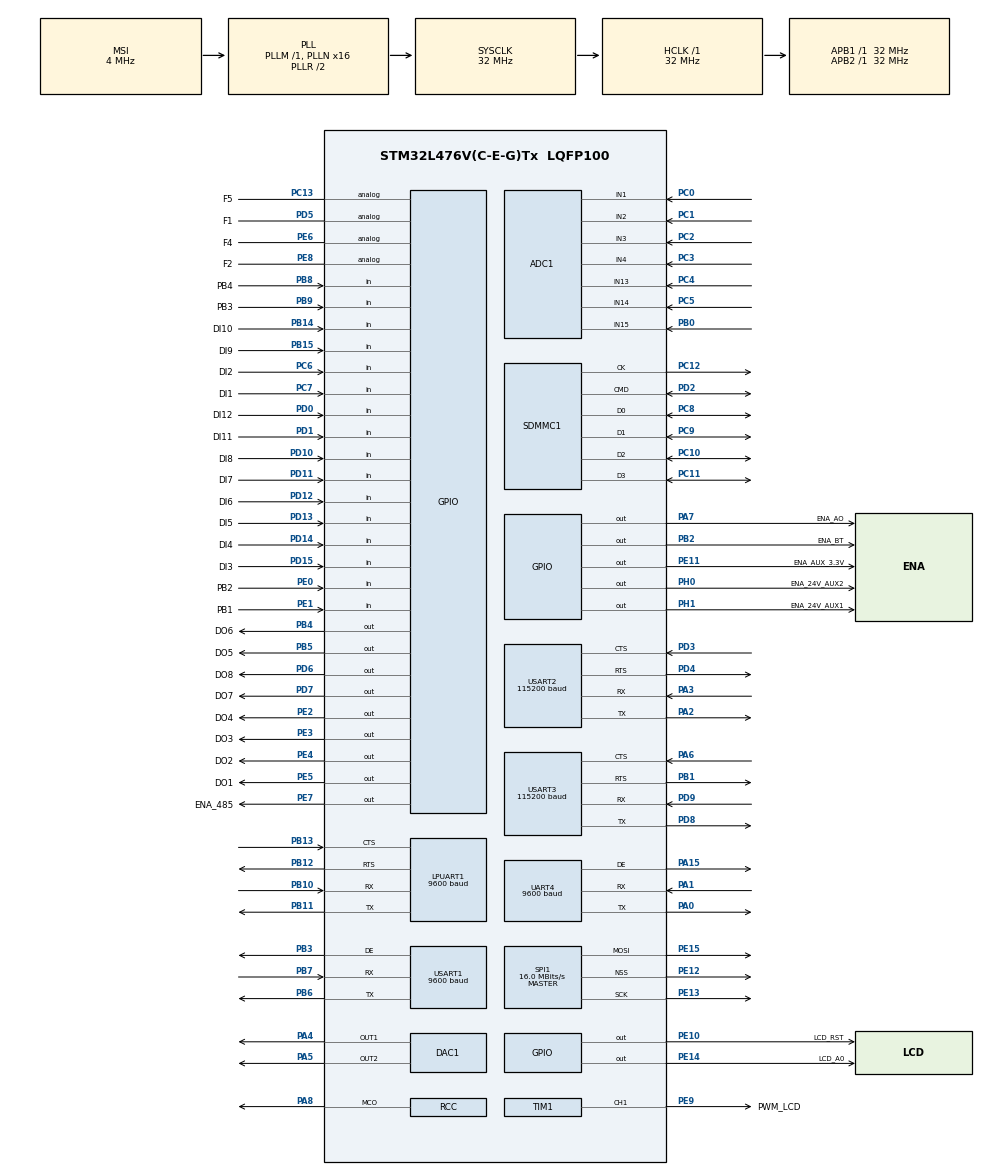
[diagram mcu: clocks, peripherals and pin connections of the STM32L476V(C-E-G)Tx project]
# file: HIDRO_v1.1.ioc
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ADC1.Channel-0\#ChannelRegularConversion=ADC_CHANNEL_4
ADC1.ClockPrescaler=ADC_CLOCK_ASYNC_DIV2
ADC1.NbrOfConversion=1
ADC1.NbrOfConversionFlag=1
ADC1.OffsetNumber-0\#ChannelRegularConversion=ADC_OFFSET_NONE
ADC1.Overrun=ADC_OVR_DATA_OVERWRITTEN
ADC1.Rank-0\#ChannelRegularConversion=1
ADC1.SamplingTime-0\#ChannelRegularConversion=ADC_SAMPLETIME_2CYCLES_5
ADC1.master=1
DAC1.DAC_Channel-DAC_OUT2=DAC_CHANNEL_2
Dma.Request0=SDMMC1_RX
Dma.Request1=SDMMC1_TX
Dma.SDMMC1_RX.0.Direction=DMA_PERIPH_TO_MEMORY
Dma.SDMMC1_RX.0.Instance=DMA2_Channel4
Dma.SDMMC1_RX.0.MemDataAlignment=DMA_MDATAALIGN_WORD
Dma.SDMMC1_RX.0.MemInc=DMA_MINC_ENABLE
Dma.SDMMC1_RX.0.Mode=DMA_NORMAL
Dma.SDMMC1_RX.0.PeriphDataAlignment=DMA_PDATAALIGN_WORD
Dma.SDMMC1_RX.0.PeriphInc=DMA_PINC_DISABLE
Dma.SDMMC1_RX.0.Priority=DMA_PRIORITY_LOW
Dma.SDMMC1_TX.1.Direction=DMA_MEMORY_TO_PERIPH
Dma.SDMMC1_TX.1.Instance=DMA2_Channel5
Dma.SDMMC1_TX.1.MemDataAlignment=DMA_MDATAALIGN_WORD
Dma.SDMMC1_TX.1.MemInc=DMA_MINC_ENABLE
Dma.SDMMC1_TX.1.Mode=DMA_NORMAL
Dma.SDMMC1_TX.1.PeriphDataAlignment=DMA_PDATAALIGN_WORD
Dma.SDMMC1_TX.1.PeriphInc=DMA_PINC_DISABLE
Dma.SDMMC1_TX.1.Priority=DMA_PRIORITY_LOW
FATFS.BSP.number=1
FATFS0.BSP.STBoard=false
FATFS0.BSP.api=Unknown
FATFS0.BSP.i2caddr=0
FATFS0.BSP.instance=PC7
FATFS0.BSP.ip=GPIO
FATFS0.BSP.mode=Input
FATFS0.BSP.name=Detect_SDIO
FATFS0.BSP.solution=PC7
IWDG.Prescaler=IWDG_PRESCALER_32
LPUART1.BaudRate=9600
LPUART1.WordLength=UART_WORDLENGTH_8B
Mcu.Family=STM32L4
Mcu.Name=STM32L476V(C-E-G)Tx
Mcu.Package=LQFP100
NVIC.DMA2_Channel4_IRQn=true\:0\:0\:false\:false\:true\:false\:true
NVIC.DMA2_Channel5_IRQn=true\:0\:0\:false\:false\:true\:false\:true
NVIC.LPUART1_IRQn=true\:0\:0\:false\:true\:true\:6\:true\:true
NVIC.PriorityGroup=NVIC_PRIORITYGROUP_4
NVIC.RTC_WKUP_IRQn=true\:0\:0\:false\:true\:true\:1\:true\:true
NVIC.SDMMC1_IRQn=true\:0\:0\:false\:false\:true\:true\:true
NVIC.UART4_IRQn=true\:0\:0\:false\:true\:true\:5\:true\:true
NVIC.USART1_IRQn=true\:0\:0\:false\:true\:true\:2\:true\:true
NVIC.USART2_IRQn=true\:0\:0\:false\:true\:true\:3\:true\:true
NVIC.USART3_IRQn=true\:0\:0\:false\:true\:true\:4\:true\:true
PA0.Mode=Asynchronous
PA0.Signal=UART4_TX
PA1.Mode=Asynchronous
PA1.Signal=UART4_RX
PA10.Signal=USB_OTG_FS_ID
PA11.Signal=USB_OTG_FS_DM
PA12.Signal=USB_OTG_FS_DP
PA13\ (JTMS-SWDIO).Mode=Serial_Wire
PA13\ (JTMS-SWDIO).Signal=SYS_JTMS-SWDIO
PA14\ (JTCK-SWCLK).Mode=Serial_Wire
PA14\ (JTCK-SWCLK).Signal=SYS_JTCK-SWCLK
PA15\ (JTDI).Mode=Hardware Flow Control (RS485)
PA15\ (JTDI).Signal=UART4_DE
PA2.Mode=Asynchronous
PA2.Signal=USART2_TX
PA3.Mode=Asynchronous
PA3.Signal=USART2_RX
PA4.Signal=COMP_DAC11_group
PA5.Signal=COMP_DAC12_group
PA6.Mode=CTS_RTS
PA6.Signal=USART3_CTS
PA7.GPIO_Label=ENA_AO
PA7.Signal=GPIO_Output
PA8.Mode=Clock-out
PA8.Signal=RCC_MCO
PA9.Signal=USB_OTG_FS_VBUS
PB0.Signal=ADCx_IN15
PB1.Mode=CTS_RTS
PB1.Signal=USART3_RTS
PB10.Mode=Asynchronous
PB10.Signal=LPUART1_RX
PB11.Mode=Asynchronous
PB11.Signal=LPUART1_TX
PB12.Mode=CTS_RTS
PB12.Signal=LPUART1_RTS
PB13.Mode=CTS_RTS
PB13.Signal=LPUART1_CTS
PB14.GPIO_Label=DI10
PB14.Signal=GPIO_Input
PB15.GPIO_Label=DI9
PB15.Signal=GPIO_Input
PB2.GPIO_Label=ENA_BT
PB2.PinState=GPIO_PIN_SET
PB2.Signal=GPIO_Output
PB3\ (JTDO-TRACESWO).Mode=Hardware Flow Control (RS485)
PB3\ (JTDO-TRACESWO).Signal=USART1_DE
PB4\ (NJTRST).GPIO_Label=DO6
PB4\ (NJTRST).Signal=GPIO_Output
PB5.GPIO_Label=DO5
PB5.Signal=GPIO_Output
PB6.Mode=Asynchronous
PB6.Signal=USART1_TX
PB7.Mode=Asynchronous
PB7.Signal=USART1_RX
PB8.GPIO_Label=PB4
PB8.Signal=GPIO_Input
PB9.GPIO_Label=PB3
PB9.Signal=GPIO_Input
PC0.Signal=ADCx_IN1
PC1.Signal=ADCx_IN2
PC10.Mode=SD_4_bits_Wide_bus
PC10.Signal=SDMMC1_D2
PC11.Mode=SD_4_bits_Wide_bus
PC11.Signal=SDMMC1_D3
PC12.Mode=SD_4_bits_Wide_bus
PC12.Signal=SDMMC1_CK
PC13.GPIO_Label=F5
PC13.Signal=GPIO_Analog
PC14-OSC32_IN\ (PC14).Mode=LSE-External-Oscillator
PC14-OSC32_IN\ (PC14).Signal=RCC_OSC32_IN
PC15-OSC32_OUT\ (PC15).Mode=LSE-External-Oscillator
PC15-OSC32_OUT\ (PC15).Signal=RCC_OSC32_OUT
PC2.Signal=ADCx_IN3
PC3.Signal=ADCx_IN4
PC4.Signal=ADCx_IN13
PC5.Signal=ADCx_IN14
PC6.GPIO_Label=DI2
PC6.Signal=GPIO_Input
PC7.GPIO_Label=DI1
PC7.Signal=GPIO_Input
PC8.Mode=SD_4_bits_Wide_bus
PC8.Signal=SDMMC1_D0
PC9.Mode=SD_4_bits_Wide_bus
PC9.Signal=SDMMC1_D1
PD0.GPIO_Label=DI12
PD0.Signal=GPIO_Input
PD1.GPIO_Label=DI11
PD1.Signal=GPIO_Input
PD10.GPIO_Label=DI8
PD10.Signal=GPIO_Input
PD11.GPIO_Label=DI7
PD11.Signal=GPIO_Input
PD12.GPIO_Label=DI6
PD12.Signal=GPIO_Input
PD13.GPIO_Label=DI5
PD13.Signal=GPIO_Input
PD14.GPIO_Label=DI4
PD14.Signal=GPIO_Input
PD15.GPIO_Label=DI3
PD15.Signal=GPIO_Input
PD2.Mode=SD_4_bits_Wide_bus
PD2.Signal=SDMMC1_CMD
PD3.Mode=CTS_RTS
PD3.Signal=USART2_CTS
PD4.Mode=CTS_RTS
PD4.Signal=USART2_RTS
PD5.GPIO_Label=F1
PD5.Signal=GPIO_Analog
PD6.GPIO_Label=DO8
PD6.Signal=GPIO_Output
PD7.GPIO_Label=DO7
PD7.Signal=GPIO_Output
PD8.Mode=Asynchronous
PD8.Signal=USART3_TX
PD9.Mode=Asynchronous
PD9.Signal=USART3_RX
PE0.GPIO_Label=PB2
PE0.Signal=GPIO_Input
PE1.GPIO_Label=PB1
PE1.Signal=GPIO_Input
PE10.GPIO_Label=LCD_RST
PE10.Signal=GPIO_Output
PE11.GPIO_Label=ENA_AUX_3.3V
PE11.Signal=GPIO_Output
PE12.Mode=NSS_Signal_Hard_Output
PE12.Signal=SPI1_NSS
PE13.Mode=TX_Only_Simplex_Unidirect_Master
PE13.Signal=SPI1_SCK
PE14.GPIO_Label=LCD_A0
PE14.Signal=GPIO_Output
PE15.Mode=TX_Only_Simplex_Unidirect_Master
PE15.Signal=SPI1_MOSI
PE2.GPIO_Label=DO4
PE2.Signal=GPIO_Output
PE3.GPIO_Label=DO3
PE3.Signal=GPIO_Output
PE4.GPIO_Label=DO2
PE4.Signal=GPIO_Output
PE5.GPIO_Label=DO1
PE5.Signal=GPIO_Output
PE6.GPIO_Label=F4
PE6.Signal=GPIO_Analog
PE7.GPIO_Label=ENA_485
PE7.PinState=GPIO_PIN_SET
PE7.Signal=GPIO_Output
PE8.GPIO_Label=F2
PE8.Signal=GPIO_Analog
PE9.GPIO_Label=PWM_LCD
PE9.Signal=S_TIM1_CH1
PH0-OSC_IN\ (PH0).GPIO_Label=ENA_24V_AUX2
PH0-OSC_IN\ (PH0).Signal=GPIO_Output
PH1-OSC_OUT\ (PH1).GPIO_Label=ENA_24V_AUX1
PH1-OSC_OUT\ (PH1).Signal=GPIO_Output
ProjectManager.HeapSize=0x400
ProjectManager.StackSize=0x800
ProjectManager.TargetToolchain=EWARM V7
RCC.ADCCLockSelection=RCC_ADCCLKSOURCE_SYSCLK
RCC.ADCFreq_Value=32000000
RCC.AHBFreq_Value=32000000
RCC.APB1Freq_Value=32000000
RCC.APB1TimFreq_Value=32000000
RCC.APB2Freq_Value=32000000
RCC.APB2TimFreq_Value=32000000
RCC.CortexFreq_Value=32000000
RCC.HCLKFreq_Value=32000000
RCC.HSE_VALUE=8000000
RCC.HSI_VALUE=16000000
RCC.LPUART1CLockSelection=RCC_LPUART1CLKSOURCE_HSI
RCC.MSI_VALUE=4000000
RCC.PLLN=16
RCC.PLLSAI1N=24
RCC.PREFETCH_ENABLE=1
RCC.RTCClockSelection=RCC_RTCCLKSOURCE_LSE
RCC.SYSCLKFreq_VALUE=32000000
RCC.SYSCLKSource=RCC_SYSCLKSOURCE_PLLCLK
RCC.UART4CLockSelection=RCC_UART4CLKSOURCE_HSI
RCC.USART1CLockSelection=RCC_USART1CLKSOURCE_HSI
RCC.USART2CLockSelection=RCC_USART2CLKSOURCE_HSI
RCC.USART3CLockSelection=RCC_USART3CLKSOURCE_HSI
RCC.USBFreq_Value=48000000
RCC.VCOOutputFreq_Value=64000000
RTC.Date=4
RTC.WakeUpClock-WakeUp=RTC_WAKEUPCLOCK_CK_SPRE_16BITS
RTC.Year=21
SDMMC1.ClockDiv=8
SH.ADCx_IN1.0=ADC1_IN1,IN1-Single-Ended
SH.ADCx_IN13.0=ADC1_IN13,IN13-Single-Ended
SH.ADCx_IN14.0=ADC1_IN14,IN14-Single-Ended
SH.ADCx_IN15.0=ADC1_IN15,IN15-Single-Ended
SH.ADCx_IN2.0=ADC1_IN2,IN2-Single-Ended
SH.ADCx_IN3.0=ADC1_IN3,IN3-Single-Ended
SH.ADCx_IN4.0=ADC1_IN4,IN4-Single-Ended
SH.COMP_DAC11_group.0=DAC1_OUT1,DAC_OUT1
SH.COMP_DAC12_group.0=DAC1_OUT2,DAC_OUT2
SH.S_TIM1_CH1.0=TIM1_CH1,PWM Generation1 CH1
SPI1.BaudRatePrescaler=SPI_BAUDRATEPRESCALER_2
SPI1.CalculateBaudRate=16.0 MBits/s
SPI1.DataSize=SPI_DATASIZE_8BIT
SPI1.Direction=SPI_DIRECTION_2LINES
SPI1.Mode=SPI_MODE_MASTER
SPI1.VirtualNSS=VM_NSSHARD
SPI1.VirtualType=VM_MASTER
TIM1.Channel-PWM\ Generation1\ CH1=TIM_CHANNEL_1
TIM1.Period=32000
TIM1.Pulse-PWM\ Generation1\ CH1=2000
TIM2.Period=0xFFFF-1
TIM2.Prescaler=32-1
UART4.BaudRate=9600
UART4.WordLength=WORDLENGTH_8B
USART1.BaudRate=9600
USART1.VirtualMode-Asynchronous=VM_ASYNC
USART1.VirtualMode-Hardware\ Flow\ Control\ (RS485)=VM_ASYNC
USART1.WordLength=WORDLENGTH_8B
USART2.BaudRate=115200
USART2.VirtualMode-Asynchronous=VM_ASYNC
USART2.WordLength=WORDLENGTH_8B
USART3.BaudRate=115200
USART3.VirtualMode-Asynchronous=VM_ASYNC
USART3.WordLength=WORDLENGTH_8B
VP_ADC1_Vref_Input.Mode=IN-Vrefint
VP_FATFS_VS_SDIO.Mode=SDIO
VP_IWDG_VS_IWDG.Mode=IWDG_Activate
VP_RTC_VS_RTC_Activate.Mode=RTC_Enabled
VP_RTC_VS_RTC_Calendar.Mode=RTC_Calendar
VP_RTC_VS_RTC_WakeUp_intern.Mode=WakeUp
VP_TIM1_VS_ClockSourceINT.Mode=Internal
VP_TIM2_VS_ClockSourceINT.Mode=Internal
board=MEP7000_v4.0

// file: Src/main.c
/* USER CODE BEGIN Header */
/**
  ******************************************************************************
  * @file           : main.c
  * @brief          : Main program body
  ******************************************************************************
  * @attention
  *
  * <h2><center>&copy; Copyright (c) 2021 STMicroelectronics.
  * All rights reserved.</center></h2>
  *
  * This software component is licensed by ST under Ultimate Liberty license
  * SLA0044, the "License"; You may not use this file except in compliance with
  * the License. You may obtain a copy of the License at:
  *                             www.st.com/SLA0044
  *
  ******************************************************************************
  */
/* USER CODE END Header */
#include "main.h"
#include "adc.h"
#include "dac.h"
#include "dma.h"
#include "fatfs.h"
#include "iwdg.h"
#include "usart.h"
#include "rtc.h"
#include "sdmmc.h"
#include "spi.h"
#include "tim.h"
#include "gpio.h"

/* USER CODE BEGIN Includes */
#include "adc_sample.h"
#include "button.h"
#include "config_flash.h"
#include "datetime.h"
#include "di.h"
#include "irrigation.h"
#include "lcd.h"
#include "sd_storage.h"
#include "ui.h"
#include "weather.h"

/* USER CODE END Includes */

/* USER CODE BEGIN PV */
/* Private variables ---------------------------------------------------------*/
volatile tREG32 Flags;
/* USER CODE END PV */

void SystemClock_Config(void);
static void MX_NVIC_Init(void);
/* USER CODE BEGIN PFP */
/* Private function prototypes -----------------------------------------------*/

/* USER CODE END PFP */

/* USER CODE BEGIN 0 */
void HAL_RTCEx_WakeUpTimerEventCallback(RTC_HandleTypeDef *hrtc)
{
  Flag_Main_1s_Event = 1;
}

/* USER CODE END 0 */

int main(void)
{

  /* MCU Configuration--------------------------------------------------------*/

  /* Reset of all peripherals, Initializes the Flash interface and the Systick. */
  HAL_Init();

  /* Configure the system clock */
  SystemClock_Config();

  /* USER CODE BEGIN SysInit */

//  HAL_SYSCFG_EnableVREFBUF(); // Enable
//  HAL_SYSCFG_VREFBUF_VoltageScalingConfig(SYSCFG_VREFBUF_VOLTAGE_SCALE1); // 2.5V
//  HAL_SYSCFG_VREFBUF_HighImpedanceConfig(SYSCFG_VREFBUF_HIGH_IMPEDANCE_DISABLE); // Vref+ connected to Vrefbuf
//  HAL_SYSCFG_DisableVREFBUF();

  /* USER CODE END SysInit */

  /* Initialize all configured peripherals */
  MX_GPIO_Init();
  MX_DMA_Init();
  MX_ADC1_Init();
  MX_DAC1_Init();
  MX_IWDG_Init();
  MX_LPUART1_UART_Init();
  MX_UART4_Init();
  MX_USART1_UART_Init();
  MX_USART2_UART_Init();
  MX_USART3_UART_Init();
  MX_RTC_Init();
  MX_SDMMC1_SD_Init();
  MX_SPI1_Init();
  MX_TIM1_Init();
  MX_TIM2_Init();
  MX_FATFS_Init();

  /* Initialize interrupts */
  MX_NVIC_Init();
  /* USER CODE BEGIN 2 */

  // Load flash into ram
  get_flash();

  // Inits
  LCDInit();
  Flag_LCD_On = 1;
  refresh_global_datetime();
  ui_init();
  clear_buttons();
  sd_init();

  HAL_TIM_Base_Start(&htim2);
	HAL_GPIO_WritePin(DO8_GPIO_Port, DO8_Pin, GPIO_PIN_SET);

  Flag_ADC_Electrode_Ready = 1;            //BORRAR, SOLO PARA PUREBA

  /* USER CODE END 2 */

  /* Infinite loop */
  while (1)
  {

    /* USER CODE BEGIN 3 */
    // One second tick
    if(Flag_Main_1s_Event)
    {
      Flag_Main_1s_Event = 0;
      iwdg_refresh();
      refresh_global_datetime();

//      adc_1s_tick();      No sirve para nada
      irrigation_1s_tick();
      weather_1s_tick();
      ui_1s_tick();
      sd_1s_tick();

    //! ! ! ! ! ! ! ! ! ! ! ! ! ! ! ! ! ! ! ! ! ! ! ! ! ! ! ! ! ! ! ! ! ! ! ! !
      Flag_ADC_Cmd_Ph=1;
      Flag_ADC_Cmd_Ec=1;
      //! ! ! ! ! ! ! ! ! ! ! ! ! ! ! ! ! ! ! ! ! ! ! ! ! ! ! ! ! ! ! ! ! ! ! ! !
    }

    adc_task();
    buttons_task();
    di_task();
    irrigation_task();
    weather_task();
    ui_task();
    sd_task();

  }
  /* USER CODE END 3 */
}

void SystemClock_Config(void)
{
  RCC_OscInitTypeDef RCC_OscInitStruct = {0};
  RCC_ClkInitTypeDef RCC_ClkInitStruct = {0};
  RCC_PeriphCLKInitTypeDef PeriphClkInit = {0};

  /** Configure LSE Drive Capability
  */
  HAL_PWR_EnableBkUpAccess();
  __HAL_RCC_LSEDRIVE_CONFIG(RCC_LSEDRIVE_LOW);
  /** Initializes the RCC Oscillators according to the specified parameters
  * in the RCC_OscInitTypeDef structure.
  */
  RCC_OscInitStruct.OscillatorType = RCC_OSCILLATORTYPE_HSI|RCC_OSCILLATORTYPE_LSI
                              |RCC_OSCILLATORTYPE_LSE|RCC_OSCILLATORTYPE_MSI;
  RCC_OscInitStruct.LSEState = RCC_LSE_ON;
  RCC_OscInitStruct.HSIState = RCC_HSI_ON;
  RCC_OscInitStruct.HSICalibrationValue = RCC_HSICALIBRATION_DEFAULT;
  RCC_OscInitStruct.LSIState = RCC_LSI_ON;
  RCC_OscInitStruct.MSIState = RCC_MSI_ON;
  RCC_OscInitStruct.MSICalibrationValue = 0;
  RCC_OscInitStruct.MSIClockRange = RCC_MSIRANGE_6;
  RCC_OscInitStruct.PLL.PLLState = RCC_PLL_ON;
  RCC_OscInitStruct.PLL.PLLSource = RCC_PLLSOURCE_MSI;
  RCC_OscInitStruct.PLL.PLLM = 1;
  RCC_OscInitStruct.PLL.PLLN = 16;
  RCC_OscInitStruct.PLL.PLLP = RCC_PLLP_DIV7;
  RCC_OscInitStruct.PLL.PLLQ = RCC_PLLQ_DIV2;
  RCC_OscInitStruct.PLL.PLLR = RCC_PLLR_DIV2;
  if (HAL_RCC_OscConfig(&RCC_OscInitStruct) != HAL_OK)
  {
    Error_Handler();
  }
  /** Initializes the CPU, AHB and APB buses clocks
  */
  RCC_ClkInitStruct.ClockType = RCC_CLOCKTYPE_HCLK|RCC_CLOCKTYPE_SYSCLK
                              |RCC_CLOCKTYPE_PCLK1|RCC_CLOCKTYPE_PCLK2;
  RCC_ClkInitStruct.SYSCLKSource = RCC_SYSCLKSOURCE_PLLCLK;
  RCC_ClkInitStruct.AHBCLKDivider = RCC_SYSCLK_DIV1;
  RCC_ClkInitStruct.APB1CLKDivider = RCC_HCLK_DIV1;
  RCC_ClkInitStruct.APB2CLKDivider = RCC_HCLK_DIV1;

  if (HAL_RCC_ClockConfig(&RCC_ClkInitStruct, FLASH_LATENCY_1) != HAL_OK)
  {
    Error_Handler();
  }
  PeriphClkInit.PeriphClockSelection = RCC_PERIPHCLK_RTC|RCC_PERIPHCLK_USART1
                              |RCC_PERIPHCLK_USART2|RCC_PERIPHCLK_USART3
                              |RCC_PERIPHCLK_UART4|RCC_PERIPHCLK_LPUART1
                              |RCC_PERIPHCLK_SDMMC1|RCC_PERIPHCLK_ADC;
  PeriphClkInit.Usart1ClockSelection = RCC_USART1CLKSOURCE_HSI;
  PeriphClkInit.Usart2ClockSelection = RCC_USART2CLKSOURCE_HSI;
  PeriphClkInit.Usart3ClockSelection = RCC_USART3CLKSOURCE_HSI;
  PeriphClkInit.Uart4ClockSelection = RCC_UART4CLKSOURCE_HSI;
  PeriphClkInit.Lpuart1ClockSelection = RCC_LPUART1CLKSOURCE_HSI;
  PeriphClkInit.AdcClockSelection = RCC_ADCCLKSOURCE_SYSCLK;
  PeriphClkInit.RTCClockSelection = RCC_RTCCLKSOURCE_LSE;
  PeriphClkInit.Sdmmc1ClockSelection = RCC_SDMMC1CLKSOURCE_PLLSAI1;
  PeriphClkInit.PLLSAI1.PLLSAI1Source = RCC_PLLSOURCE_MSI;
  PeriphClkInit.PLLSAI1.PLLSAI1M = 1;
  PeriphClkInit.PLLSAI1.PLLSAI1N = 24;
  PeriphClkInit.PLLSAI1.PLLSAI1P = RCC_PLLP_DIV7;
  PeriphClkInit.PLLSAI1.PLLSAI1Q = RCC_PLLQ_DIV2;
  PeriphClkInit.PLLSAI1.PLLSAI1R = RCC_PLLR_DIV2;
  PeriphClkInit.PLLSAI1.PLLSAI1ClockOut = RCC_PLLSAI1_48M2CLK;
  if (HAL_RCCEx_PeriphCLKConfig(&PeriphClkInit) != HAL_OK)
  {
    Error_Handler();
  }
  HAL_RCC_MCOConfig(RCC_MCO1, RCC_MCO1SOURCE_SYSCLK, RCC_MCODIV_1);
  /** Configure the main internal regulator output voltage
  */
  if (HAL_PWREx_ControlVoltageScaling(PWR_REGULATOR_VOLTAGE_SCALE1) != HAL_OK)
  {
    Error_Handler();
  }
  /** Enable MSI Auto calibration
  */
  HAL_RCCEx_EnableMSIPLLMode();
}

/**
  * @brief NVIC Configuration.
  * @retval None
  */
static void MX_NVIC_Init(void)
{
  /* RTC_WKUP_IRQn interrupt configuration */
  HAL_NVIC_SetPriority(RTC_WKUP_IRQn, 0, 0);
  HAL_NVIC_EnableIRQ(RTC_WKUP_IRQn);
  /* USART1_IRQn interrupt configuration */
  HAL_NVIC_SetPriority(USART1_IRQn, 0, 0);
  HAL_NVIC_EnableIRQ(USART1_IRQn);
  /* USART2_IRQn interrupt configuration */
  HAL_NVIC_SetPriority(USART2_IRQn, 0, 0);
  HAL_NVIC_EnableIRQ(USART2_IRQn);
  /* USART3_IRQn interrupt configuration */
  HAL_NVIC_SetPriority(USART3_IRQn, 0, 0);
  HAL_NVIC_EnableIRQ(USART3_IRQn);
  /* UART4_IRQn interrupt configuration */
  HAL_NVIC_SetPriority(UART4_IRQn, 0, 0);
  HAL_NVIC_EnableIRQ(UART4_IRQn);
  /* LPUART1_IRQn interrupt configuration */
  HAL_NVIC_SetPriority(LPUART1_IRQn, 0, 0);
  HAL_NVIC_EnableIRQ(LPUART1_IRQn);
}

void Error_Handler(void)
{
  while(1)
  {
  }
}

/************************ (C) COPYRIGHT STMicroelectronics *****END OF FILE****/
